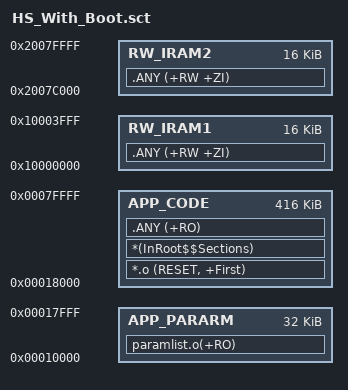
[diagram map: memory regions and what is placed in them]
; *************************************************************
; *** Scatter-Loading Description File generated by uVision ***
; *************************************************************

LR_IROM1 0x00018000 0x00068000  {    ; load region size_region
  APP_CODE 0x00018000 0x00068000  {  ; load address = execution address
   *.o (RESET, +First)
   *(InRoot$$Sections)
   .ANY (+RO)
  }
  RW_IRAM1 0x10000000 0x00004000  {  ; RW data
   .ANY (+RW +ZI)
  }
  RW_IRAM2 0x2007C000 0x00004000  {  ; RW data
   .ANY (+RW +ZI)
  }
}

; 参数区
LR_IROM2 0x00010000 0x00008000  {    ; load region size_region
  APP_PARARM 0x0010000 0x00008000  {  ; load address = execution address
	paramlist.o(+RO)
  }
}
